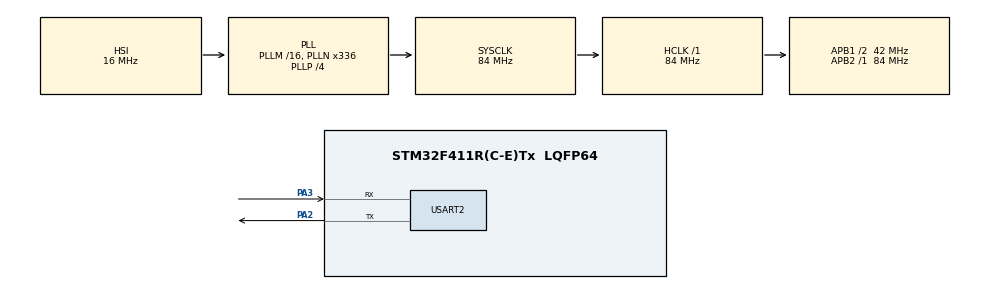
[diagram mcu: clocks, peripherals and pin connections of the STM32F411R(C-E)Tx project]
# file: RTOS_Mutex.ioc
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FREERTOS.Mutexes01=myMutex,Dynamic,NULL,Available
FREERTOS.Tasks01=stm32,32,128,stm32Task,Default,NULL,Dynamic,NULL,NULL;esp32,32,128,esp32Task,Default,NULL,Dynamic,NULL,NULL
FREERTOS.configUSE_NEWLIB_REENTRANT=1
Mcu.Family=STM32F4
Mcu.Name=STM32F411R(C-E)Tx
Mcu.Package=LQFP64
NVIC.PriorityGroup=NVIC_PRIORITYGROUP_4
NVIC.TIM5_IRQn=true\:15\:0\:false\:false\:true\:false\:false\:true\:true
NVIC.TimeBase=TIM5_IRQn
NVIC.TimeBaseIP=TIM5
PA13.Mode=Serial_Wire
PA13.Signal=SYS_JTMS-SWDIO
PA14.Mode=Serial_Wire
PA14.Signal=SYS_JTCK-SWCLK
PA2.Mode=Asynchronous
PA2.Signal=USART2_TX
PA3.Mode=Asynchronous
PA3.Signal=USART2_RX
ProjectManager.HeapSize=0x200
ProjectManager.StackSize=0x400
ProjectManager.TargetToolchain=STM32CubeIDE
RCC.48MHZClocksFreq_Value=84000000
RCC.AHBFreq_Value=84000000
RCC.APB1CLKDivider=RCC_HCLK_DIV2
RCC.APB1Freq_Value=42000000
RCC.APB1TimFreq_Value=84000000
RCC.APB2Freq_Value=84000000
RCC.APB2TimFreq_Value=84000000
RCC.CortexFreq_Value=84000000
RCC.FLatency-AdvancedSettings=FLASH_LATENCY_2
RCC.HCLKFreq_Value=84000000
RCC.HSE_VALUE=8000000
RCC.HSI_VALUE=16000000
RCC.PLLN=336
RCC.PLLP=RCC_PLLP_DIV4
RCC.SYSCLKFreq_VALUE=84000000
RCC.SYSCLKSource=RCC_SYSCLKSOURCE_PLLCLK
RCC.VCOOutputFreq_Value=336000000
USART2.VirtualMode=VM_ASYNC
VP_FREERTOS_VS_CMSIS_V2.Mode=CMSIS_V2
VP_SYS_VS_tim5.Mode=TIM5
board=NUCLEO-F411RE

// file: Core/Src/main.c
/* USER CODE BEGIN Header */
/**
 ******************************************************************************
 * @file           : main.c
 * @brief          : Main program body
 ******************************************************************************
 * @attention
 *
 * Copyright (c) 2025 STMicroelectronics.
 * All rights reserved.
 *
 * This software is licensed under terms that can be found in the LICENSE file
 * in the root directory of this software component.
 * If no LICENSE file comes with this software, it is provided AS-IS.
 *
 ******************************************************************************
 */
/* USER CODE END Header */
#include "main.h"
#include "cmsis_os.h"

/* USER CODE BEGIN Includes */
#include "stdio.h"
/* USER CODE END Includes */

UART_HandleTypeDef huart2;

/* Definitions for stm32 */
osThreadId_t stm32Handle;
const osThreadAttr_t stm32_attributes =
		{ .name = "stm32", .stack_size = 128 * 4, .priority =
				(osPriority_t) osPriorityAboveNormal, };
/* Definitions for esp32 */
osThreadId_t esp32Handle;
const osThreadAttr_t esp32_attributes =
		{ .name = "esp32", .stack_size = 128 * 4, .priority =
				(osPriority_t) osPriorityAboveNormal, };
/* Definitions for myMutex */
osMutexId_t myMutexHandle;
const osMutexAttr_t myMutex_attributes = { .name = "myMutex" };
/* USER CODE BEGIN PV */
char sharedResource[10];
/* USER CODE END PV */

void SystemClock_Config(void);
static void MX_GPIO_Init(void);
static void MX_USART2_UART_Init(void);
void stm32Task(void *argument);
void esp32Task(void *argument);

/* USER CODE BEGIN 0 */
int _write(int file, char *ptr, int len) {
	/* Implement your write code here, this is used by puts and printf for example */
	int i = 0;
	for (i = 0; i < len; i++)
		ITM_SendChar((*ptr++));
	return len;
}

/* USER CODE END 0 */

int main(void) {

	/* MCU Configuration--------------------------------------------------------*/

	/* Reset of all peripherals, Initializes the Flash interface and the Systick. */
	HAL_Init();

	/* Configure the system clock */
	SystemClock_Config();

	/* Initialize all configured peripherals */
	MX_GPIO_Init();
	MX_USART2_UART_Init();

	/* Init scheduler */
	osKernelInitialize();
	/* Create the mutex(es) */
	/* creation of myMutex */
	myMutexHandle = osMutexNew(&myMutex_attributes);

	/* Create the thread(s) */
	/* creation of stm32 */
	stm32Handle = osThreadNew(stm32Task, NULL, &stm32_attributes);

	/* creation of esp32 */
	esp32Handle = osThreadNew(esp32Task, NULL, &esp32_attributes);

	/* Start scheduler */
	osKernelStart();

	/* We should never get here as control is now taken by the scheduler */

	/* Infinite loop */
	while (1) {

	}
}

void SystemClock_Config(void) {
	RCC_OscInitTypeDef RCC_OscInitStruct = { 0 };
	RCC_ClkInitTypeDef RCC_ClkInitStruct = { 0 };

	/** Configure the main internal regulator output voltage
	 */
	__HAL_RCC_PWR_CLK_ENABLE();
	__HAL_PWR_VOLTAGESCALING_CONFIG(PWR_REGULATOR_VOLTAGE_SCALE1);

	/** Initializes the RCC Oscillators according to the specified parameters
	 * in the RCC_OscInitTypeDef structure.
	 */
	RCC_OscInitStruct.OscillatorType = RCC_OSCILLATORTYPE_HSI;
	RCC_OscInitStruct.HSIState = RCC_HSI_ON;
	RCC_OscInitStruct.HSICalibrationValue = RCC_HSICALIBRATION_DEFAULT;
	RCC_OscInitStruct.PLL.PLLState = RCC_PLL_ON;
	RCC_OscInitStruct.PLL.PLLSource = RCC_PLLSOURCE_HSI;
	RCC_OscInitStruct.PLL.PLLM = 16;
	RCC_OscInitStruct.PLL.PLLN = 336;
	RCC_OscInitStruct.PLL.PLLP = RCC_PLLP_DIV4;
	RCC_OscInitStruct.PLL.PLLQ = 4;
	if (HAL_RCC_OscConfig(&RCC_OscInitStruct) != HAL_OK) {
		Error_Handler();
	}

	/** Initializes the CPU, AHB and APB buses clocks
	 */
	RCC_ClkInitStruct.ClockType = RCC_CLOCKTYPE_HCLK | RCC_CLOCKTYPE_SYSCLK
			| RCC_CLOCKTYPE_PCLK1 | RCC_CLOCKTYPE_PCLK2;
	RCC_ClkInitStruct.SYSCLKSource = RCC_SYSCLKSOURCE_PLLCLK;
	RCC_ClkInitStruct.AHBCLKDivider = RCC_SYSCLK_DIV1;
	RCC_ClkInitStruct.APB1CLKDivider = RCC_HCLK_DIV2;
	RCC_ClkInitStruct.APB2CLKDivider = RCC_HCLK_DIV1;

	if (HAL_RCC_ClockConfig(&RCC_ClkInitStruct, FLASH_LATENCY_2) != HAL_OK) {
		Error_Handler();
	}
}

static void MX_USART2_UART_Init(void) {

	huart2.Instance = USART2;
	huart2.Init.BaudRate = 115200;
	huart2.Init.WordLength = UART_WORDLENGTH_8B;
	huart2.Init.StopBits = UART_STOPBITS_1;
	huart2.Init.Parity = UART_PARITY_NONE;
	huart2.Init.Mode = UART_MODE_TX_RX;
	huart2.Init.HwFlowCtl = UART_HWCONTROL_NONE;
	huart2.Init.OverSampling = UART_OVERSAMPLING_16;
	if (HAL_UART_Init(&huart2) != HAL_OK) {
		Error_Handler();
	}

}

static void MX_GPIO_Init(void) {

	/* GPIO Ports Clock Enable */
	__HAL_RCC_GPIOA_CLK_ENABLE();

}

void stm32Task(void *argument) {
	/* USER CODE BEGIN 5 */
	/* Infinite loop */

	char stm32[] = "stm32";
	for (;;) {
		if (osMutexAcquire(myMutexHandle, osWaitForever) == osOK) {
			int i;
			for (int i = 0; i < 5; i++) {
				sharedResource[i] = stm32[i];
				osDelay(50);
			}
			sharedResource[5] = '\0';
			printf("STM32:%s\r\n", sharedResource);
			osMutexRelease(myMutexHandle);
		}
		osDelay(100);
	}
	/* USER CODE END 5 */
}

void esp32Task(void *argument) {
	/* USER CODE BEGIN esp32Task */
	/* Infinite loop */
	char esp32[] = "esp32";
	for (;;) {
		if (osMutexAcquire(myMutexHandle, osWaitForever) == osOK) {
			int i;
			for (int i = 0; i < 5; i++) {
				sharedResource[i] = esp32[i];
				osDelay(50);

			}
			sharedResource[5] = '\0';
			printf("ESP32:%s\r\n", sharedResource);
			osMutexRelease(myMutexHandle);
		}
		osDelay(100);
	}
	/* USER CODE END esp32Task */
}

void HAL_TIM_PeriodElapsedCallback(TIM_HandleTypeDef *htim) {
	if (htim->Instance == TIM5) {
		HAL_IncTick();
	}
}

void Error_Handler(void) {
	__disable_irq();
	while (1) {
	}
}
